AUTOSAR XML (schema 4-3-0)
package /ComponentTypes
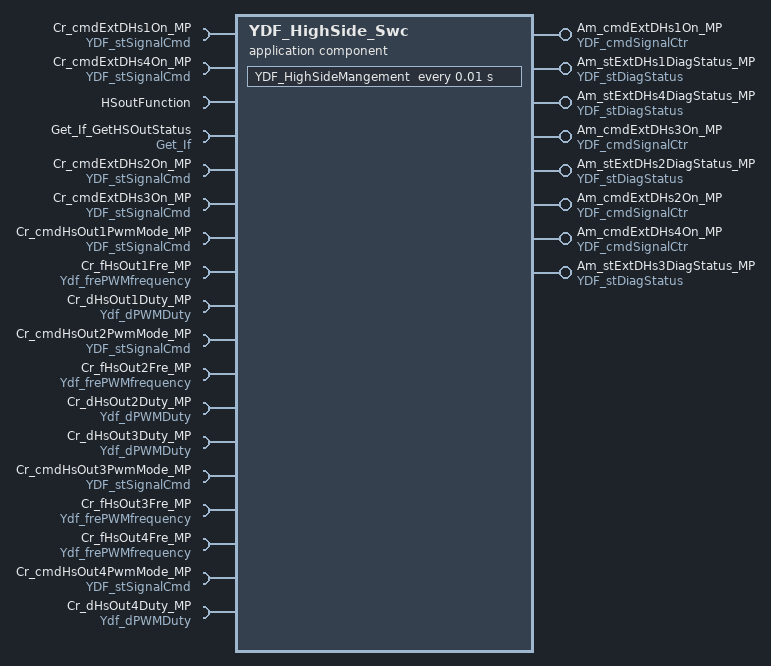
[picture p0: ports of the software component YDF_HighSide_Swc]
  application sw component type YDF_HighSide_Swc
    require port Cr_cmdExtDHs1On_MP: nonqueued-receiver-com-spec{data-element=SignalCmd, init-value=0}, required-interface=YDF_stSignalCmd
    require port Cr_cmdExtDHs4On_MP: nonqueued-receiver-com-spec{data-element=SignalCmd, init-value=0}, required-interface=YDF_stSignalCmd
    4 x provide port:
      Am_cmdExtDHs1On_MP: nonqueued-sender-com-spec{data-element=OutputCtr, init-value=0}, provided-interface=YDF_cmdSignalCtr
      Am_stExtDHs1DiagStatus_MP: nonqueued-sender-com-spec{data-element=DiagStatus, init-value=0}, provided-interface=YDF_stDiagStatus
      Am_stExtDHs4DiagStatus_MP: nonqueued-sender-com-spec{data-element=DiagStatus, init-value=0}, provided-interface=YDF_stDiagStatus
      Am_cmdExtDHs3On_MP: nonqueued-sender-com-spec{data-element=OutputCtr, init-value=0}, provided-interface=YDF_cmdSignalCtr
    4 x require port:
      HSoutFunction: required-com-specs=[High_Side1_Function, High_Side2_Function, High_Side3_Function, High_Side4_Function], required-interface=HSoutFunction
      Get_If_GetHSOutStatus: required-interface=Get_If
        required-com-specs:
          Get_Ad_Result
          Get_io_inResult
          Get_BTS_OutResult
          Get_CAN_ActiveInf
          Icu_17_GtmCcu6_PWMIN_CH{1..4}
          Icu_17_GtmCcu6_PWMIN_PWMSCB1
          Icu_17_GtmCcu6_PWMIN_PWMSCB2
          Icu_17_GtmCcu6_PWMIN_LAMPSCB1
          Icu_17_GtmCcu6_PWMIN_LAMPSCB2
          Get_Bottom_Ver
          Get_SentData
          Get_Level_OutResult
          Get_PwmOrLevel_OutResult
          Get_Motor_OutResult
      Cr_cmdExtDHs2On_MP: nonqueued-receiver-com-spec{data-element=SignalCmd, init-value=0}, required-interface=YDF_stSignalCmd
      Cr_cmdExtDHs3On_MP: nonqueued-receiver-com-spec{data-element=SignalCmd, init-value=0}, required-interface=YDF_stSignalCmd
    4 x provide port:
      Am_stExtDHs2DiagStatus_MP: nonqueued-sender-com-spec{data-element=DiagStatus, init-value=0}, provided-interface=YDF_stDiagStatus
      Am_cmdExtDHs2On_MP: nonqueued-sender-com-spec{data-element=OutputCtr, init-value=0}, provided-interface=YDF_cmdSignalCtr
      Am_cmdExtDHs4On_MP: nonqueued-sender-com-spec{data-element=OutputCtr, init-value=0}, provided-interface=YDF_cmdSignalCtr
      Am_stExtDHs3DiagStatus_MP: nonqueued-sender-com-spec{data-element=DiagStatus, init-value=0}, provided-interface=YDF_stDiagStatus
    12 x require port:
      Cr_cmdHsOut1PwmMode_MP: nonqueued-receiver-com-spec{data-element=SignalCmd, init-value=0}, required-interface=YDF_stSignalCmd
      Cr_fHsOut1Fre_MP: nonqueued-receiver-com-spec{data-element=PWMfrequency, filter=data-filter-type=ALWAYS, init-value=0}, required-interface=Ydf_frePWMfrequency
      Cr_dHsOut1Duty_MP: nonqueued-receiver-com-spec{data-element=PWMDuty, filter=data-filter-type=ALWAYS, init-value=0}, required-interface=Ydf_dPWMDuty
      Cr_cmdHsOut2PwmMode_MP: nonqueued-receiver-com-spec{data-element=SignalCmd, init-value=0}, required-interface=YDF_stSignalCmd
      Cr_fHsOut2Fre_MP: nonqueued-receiver-com-spec{data-element=PWMfrequency, filter=data-filter-type=ALWAYS, init-value=0}, required-interface=Ydf_frePWMfrequency
      Cr_dHsOut2Duty_MP: nonqueued-receiver-com-spec{data-element=PWMDuty, filter=data-filter-type=ALWAYS, init-value=0}, required-interface=Ydf_dPWMDuty
      Cr_dHsOut3Duty_MP: nonqueued-receiver-com-spec{data-element=PWMDuty, filter=data-filter-type=ALWAYS, init-value=0}, required-interface=Ydf_dPWMDuty
      Cr_cmdHsOut3PwmMode_MP: nonqueued-receiver-com-spec{data-element=SignalCmd, init-value=0}, required-interface=YDF_stSignalCmd
      Cr_fHsOut3Fre_MP: nonqueued-receiver-com-spec{data-element=PWMfrequency, filter=data-filter-type=ALWAYS, init-value=0}, required-interface=Ydf_frePWMfrequency
      Cr_fHsOut4Fre_MP: nonqueued-receiver-com-spec{data-element=PWMfrequency, filter=data-filter-type=ALWAYS, init-value=0}, required-interface=Ydf_frePWMfrequency
      Cr_cmdHsOut4PwmMode_MP: nonqueued-receiver-com-spec{data-element=SignalCmd, init-value=0}, required-interface=YDF_stSignalCmd
      Cr_dHsOut4Duty_MP: nonqueued-receiver-com-spec{data-element=PWMDuty, filter=data-filter-type=ALWAYS, init-value=0}, required-interface=Ydf_dPWMDuty
    behavior YDF_HighSide_Swc_InternalBehavior
      timing event TMT_YDF_HighSideMangement: start-on-event=YDF_HighSideMangement, period=0.01
      runnable YDF_HighSideMangement
        data-receive-point-by-arguments:
          16 x access:
            REC_Cr_cmdExtDHs{1..4}On_MP_SignalCmd: accessed-variable=Cr_cmdExtDHs{1..4}On_MP.SignalCmd
            REC_Cr_cmdHsOut{1..4}PwmMode_MP_SignalCmd: accessed-variable=Cr_cmdHsOut{1..4}PwmMode_MP.SignalCmd
            REC_Cr_dHsOut{1..4}Duty_MP_PWMDuty: accessed-variable=Cr_dHsOut{1..4}Duty_MP.PWMDuty
            REC_Cr_fHsOut{1..4}Fre_MP_PWMfrequency: accessed-variable=Cr_fHsOut{1..4}Fre_MP.PWMfrequency
        data-send-points:
          8 x access:
            SEND_Am_cmdExtDHs{1..4}On_MP_OutputCtr: accessed-variable=Am_cmdExtDHs{1..4}On_MP.OutputCtr
            SEND_Am_stExtDHs{1..4}DiagStatus_MP_DiagStatus: accessed-variable=Am_stExtDHs{1..4}DiagStatus_MP.DiagStatus
        5 x sync call:
          SC_Get_If_GetHSOutStatus_Get_PwmOrLevel_OutResult: operation=Get_If_GetHSOutStatus.Get_PwmOrLevel_OutResult
          SC_HSoutFunction_High_Side{1..4}_Function: operation=HSoutFunction.High_Side{1..4}_Function
  swc implementation YDF_HighSide_Swc_Implementation: behavior=YDF_HighSide_Swc_InternalBehavior
